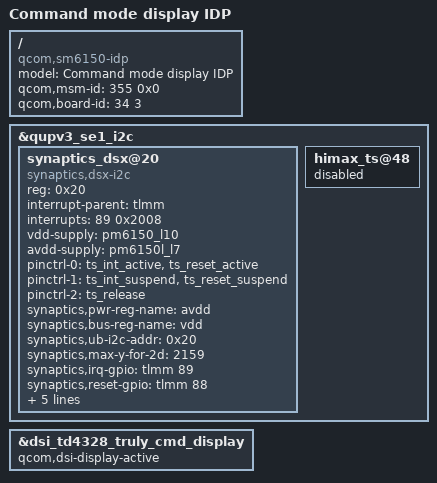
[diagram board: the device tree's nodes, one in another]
/* Copyright (c) 2018, The Linux Foundation. All rights reserved.
 *
 * This program is free software; you can redistribute it and/or modify
 * it under the terms of the GNU General Public License version 2 and
 * only version 2 as published by the Free Software Foundation.
 *
 * This program is distributed in the hope that it will be useful,
 * but WITHOUT ANY WARRANTY; without even the implied warranty of
 * MERCHANTABILITY or FITNESS FOR A PARTICULAR PURPOSE.  See the
 * GNU General Public License for more details.
 */

/dts-v1/;
/plugin/;

#include <dt-bindings/interrupt-controller/arm-gic.h>
#include <dt-bindings/clock/qcom,camcc-sm6150.h>

#include "sm6150-idp.dtsi"
#include "sm6150-audio-overlay.dtsi"

/ {
	model = "Command mode display IDP";
	compatible = "qcom,sm6150-idp", "qcom,sm6150", "qcom,idp";
	qcom,msm-id = <355 0x0>;
	qcom,board-id = <34 3>;
};

&qupv3_se1_i2c {
	synaptics_dsx@20 {
		compatible = "synaptics,dsx-i2c";
		reg = <0x20>;
		interrupt-parent = <&tlmm>;
		interrupts = <89 0x2008>;
		vdd-supply = <&pm6150_l10>;
		avdd-supply = <&pm6150l_l7>;
		pinctrl-names = "pmx_ts_active","pmx_ts_suspend",
					"pmx_ts_release";
		pinctrl-0 = <&ts_int_active &ts_reset_active>;
		pinctrl-1 = <&ts_int_suspend &ts_reset_suspend>;
		pinctrl-2 = <&ts_release>;
		synaptics,pwr-reg-name = "avdd";
		synaptics,bus-reg-name = "vdd";
		synaptics,ub-i2c-addr = <0x20>;
		synaptics,max-y-for-2d = <2159>;
		synaptics,irq-gpio = <&tlmm 89 0x2008>;
		synaptics,reset-gpio = <&tlmm 88 0x0>;
		synaptics,irq-on-state = <0>;
		synaptics,power-delay-ms = <200>;
		synaptics,reset-delay-ms = <200>;
		synaptics,reset-on-state = <0>;
		synaptics,reset-active-ms = <20>;
	};

	himax_ts@48 {
		status = "disabled";
	};
};

&dsi_td4328_truly_cmd_display {
	qcom,dsi-display-active;
};
